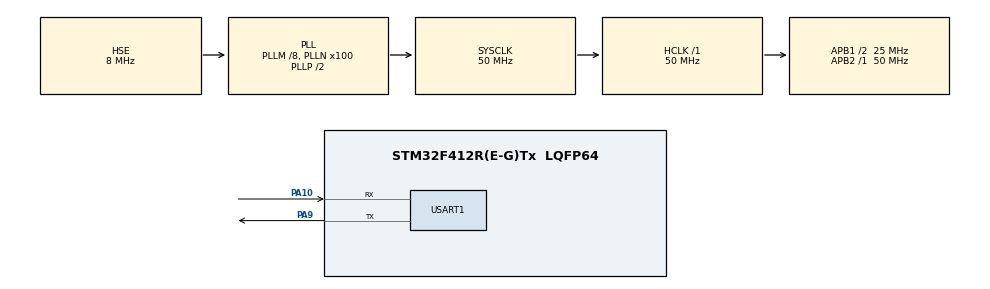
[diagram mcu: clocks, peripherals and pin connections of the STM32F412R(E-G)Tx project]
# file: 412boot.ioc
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Mcu.Family=STM32F4
Mcu.Name=STM32F412R(E-G)Tx
Mcu.Package=LQFP64
NVIC.PriorityGroup=NVIC_PRIORITYGROUP_4
NVIC.TIM2_IRQn=true\:0\:0\:false\:false\:true\:true\:true\:true
NVIC.TIM3_IRQn=true\:0\:0\:false\:false\:true\:true\:true\:true
NVIC.USART1_IRQn=true\:0\:0\:false\:false\:true\:true\:true\:true
PA10.Mode=Asynchronous
PA10.Signal=USART1_RX
PA13.Mode=Serial_Wire
PA13.Signal=SYS_JTMS-SWDIO
PA14.Mode=Serial_Wire
PA14.Signal=SYS_JTCK-SWCLK
PA9.Mode=Asynchronous
PA9.Signal=USART1_TX
PH0\ -\ OSC_IN.Mode=HSE-External-Oscillator
PH0\ -\ OSC_IN.Signal=RCC_OSC_IN
PH1\ -\ OSC_OUT.Mode=HSE-External-Oscillator
PH1\ -\ OSC_OUT.Signal=RCC_OSC_OUT
ProjectManager.HeapSize=0x200
ProjectManager.StackSize=0x400
ProjectManager.TargetToolchain=MDK-ARM V5.32
RCC.AHBFreq_Value=50000000
RCC.APB1CLKDivider=RCC_HCLK_DIV2
RCC.APB1Freq_Value=25000000
RCC.APB1TimFreq_Value=50000000
RCC.APB2Freq_Value=50000000
RCC.APB2TimFreq_Value=50000000
RCC.CortexFreq_Value=50000000
RCC.HCLKFreq_Value=50000000
RCC.HSE_VALUE=8000000
RCC.PLLM=8
RCC.PLLN=100
RCC.PLLSourceVirtual=RCC_PLLSOURCE_HSE
RCC.SYSCLKFreq_VALUE=50000000
RCC.SYSCLKSource=RCC_SYSCLKSOURCE_PLLCLK
RCC.USBFreq_Value=50000000
RCC.VCOOutputFreq_Value=100000000
TIM2.Period=10
TIM2.Prescaler=5000
TIM3.Period=10
TIM3.Prescaler=5000
USART1.VirtualMode=VM_ASYNC
VP_RTC_VS_RTC_Activate.Mode=RTC_Enabled
VP_TIM2_VS_ClockSourceINT.Mode=Internal
VP_TIM3_VS_ClockSourceINT.Mode=Internal
board=custom

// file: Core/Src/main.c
/* USER CODE BEGIN Header */
/**
  ******************************************************************************
  * @file           : main.c
  * @brief          : Main program body
  ******************************************************************************
  * @attention
  *
  * Copyright (c) 2024 STMicroelectronics.
  * All rights reserved.
  *
  * This software is licensed under terms that can be found in the LICENSE file
  * in the root directory of this software component.
  * If no LICENSE file comes with this software, it is provided AS-IS.
  *
  ******************************************************************************
  */
/* USER CODE END Header */
#include "main.h"
#include "rtc.h"
#include "tim.h"
#include "usart.h"
#include "gpio.h"

/* USER CODE BEGIN Includes */
#include "stdio.h"
#include "BspUsart1.h"
#include "BspTime2.h"
#include "BspTime3.h"
#include "common.h"
uint8_t version_data[100]   = __DATE__;
uint8_t version_time[100]   = __TIME__;
/* USER CODE END Includes */

/* USER CODE BEGIN PV */
typedef void (*pFunction)(void);
#define FLASH_ADDR_APP 0x8020000
uint8_t Jump_To_App(void)
{
	pFunction Jump_To_Application;
	uint32_t  JumpAddress;

	if (((*(__IO uint32_t*)FLASH_ADDR_APP) & 0x2FFC0000 ) == 0x20000000)
	{

		JumpAddress = *(__IO uint32_t*) (FLASH_ADDR_APP + 4);
		Jump_To_Application = (pFunction) JumpAddress;

		__set_MSP(*(__IO uint32_t*) FLASH_ADDR_APP);

		Jump_To_Application();
	}
	else
	{
		while(1);
	}

	return 1;
}
/* USER CODE END PV */

void SystemClock_Config(void);

/* USER CODE BEGIN 0 */
int read_bkup;
/* USER CODE END 0 */

int main(void)
{

  /* USER CODE BEGIN 1 */
	if(RTC->BKP0R){
		__HAL_RCC_PWR_CLK_ENABLE();
		PWR->CR |= PWR_CR_DBP;
		while((PWR->CR & PWR_CR_DBP) == RESET);

		RTC->BKP0R = 0;
		__HAL_RCC_RTC_DISABLE();
		Jump_To_App();
	}
  /* USER CODE END 1 */

  /* MCU Configuration--------------------------------------------------------*/

  /* Reset of all peripherals, Initializes the Flash interface and the Systick. */
  HAL_Init();

  /* Configure the system clock */
  SystemClock_Config();

  /* Initialize all configured peripherals */
  MX_GPIO_Init();
  MX_TIM2_Init();
  MX_TIM3_Init();
  MX_USART1_UART_Init();
  MX_RTC_Init();
  /* USER CODE BEGIN 2 */

	CommonInit();

	for(int i = 0;i<eTimMax;i++){
		g_Tim2Array[i] = 0;
	}

	printf("\r\nboot version***********************   \r\n");
	printf("%s",version_data);
	printf("%s",version_time);
	printf("\r\n***********************************   \r\n");

	while(1){
		CommonExec();
	}
  /* USER CODE END 2 */

  /* Infinite loop */
  while (1)
  {

  }
}

void SystemClock_Config(void)
{
  RCC_OscInitTypeDef RCC_OscInitStruct = {0};
  RCC_ClkInitTypeDef RCC_ClkInitStruct = {0};

  /** Configure the main internal regulator output voltage
  */
  __HAL_RCC_PWR_CLK_ENABLE();
  __HAL_PWR_VOLTAGESCALING_CONFIG(PWR_REGULATOR_VOLTAGE_SCALE1);

  /** Initializes the RCC Oscillators according to the specified parameters
  * in the RCC_OscInitTypeDef structure.
  */
  RCC_OscInitStruct.OscillatorType = RCC_OSCILLATORTYPE_LSI|RCC_OSCILLATORTYPE_HSE;
  RCC_OscInitStruct.HSEState = RCC_HSE_ON;
  RCC_OscInitStruct.LSEState = RCC_LSE_OFF;
  RCC_OscInitStruct.LSIState = RCC_LSI_ON;
  RCC_OscInitStruct.PLL.PLLState = RCC_PLL_ON;
  RCC_OscInitStruct.PLL.PLLSource = RCC_PLLSOURCE_HSE;
  RCC_OscInitStruct.PLL.PLLM = 8;
  RCC_OscInitStruct.PLL.PLLN = 100;
  RCC_OscInitStruct.PLL.PLLP = RCC_PLLP_DIV2;
  RCC_OscInitStruct.PLL.PLLQ = 2;
  RCC_OscInitStruct.PLL.PLLR = 2;
  if (HAL_RCC_OscConfig(&RCC_OscInitStruct) != HAL_OK)
  {
    Error_Handler();
  }

  /** Initializes the CPU, AHB and APB buses clocks
  */
  RCC_ClkInitStruct.ClockType = RCC_CLOCKTYPE_HCLK|RCC_CLOCKTYPE_SYSCLK
                              |RCC_CLOCKTYPE_PCLK1|RCC_CLOCKTYPE_PCLK2;
  RCC_ClkInitStruct.SYSCLKSource = RCC_SYSCLKSOURCE_PLLCLK;
  RCC_ClkInitStruct.AHBCLKDivider = RCC_SYSCLK_DIV1;
  RCC_ClkInitStruct.APB1CLKDivider = RCC_HCLK_DIV2;
  RCC_ClkInitStruct.APB2CLKDivider = RCC_HCLK_DIV1;

  if (HAL_RCC_ClockConfig(&RCC_ClkInitStruct, FLASH_LATENCY_1) != HAL_OK)
  {
    Error_Handler();
  }
}

void Error_Handler(void)
{
  __disable_irq();
  while (1)
  {
  }
}
